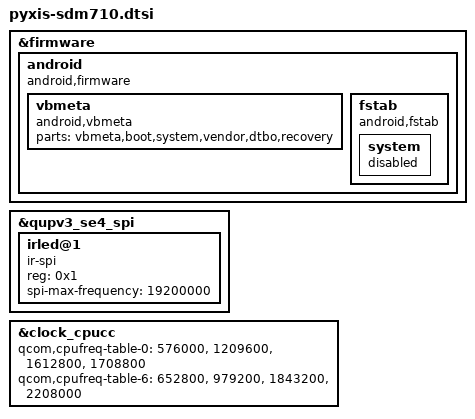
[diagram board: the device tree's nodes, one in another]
/* Copyright (c) 2018, The Linux Foundation. All rights reserved.
 * Copyright (C) 2020 XiaoMi, Inc.
 *
 * This program is free software; you can redistribute it and/or modify
 * it under the terms of the GNU General Public License version 2 and
 * only version 2 as published by the Free Software Foundation.
 *
 * This program is distributed in the hope that it will be useful,
 * but WITHOUT ANY WARRANTY; without even the implied warranty of
 * MERCHANTABILITY or FITNESS FOR A PARTICULAR PURPOSE.  See the
 * GNU General Public License for more details.
 */
#include "pyxis-cosmos-sdm710-common.dtsi"

&firmware {
	android {
		compatible = "android,firmware";
		vbmeta {
			compatible = "android,vbmeta";
			parts = "vbmeta,boot,system,vendor,dtbo,recovery";
		};

		fstab {
			compatible = "android,fstab";
			system {
				status = "disabled";
			};
		};
	};
};

&qupv3_se4_spi {
	status = "ok";
	irled@1 {
		compatible = "ir-spi";
		reg = <0x1>;
		status = "ok";
		spi-max-frequency = <19200000>;
	};
};

/* sdm670.dtsi */
&clock_cpucc {
	qcom,cpufreq-table-0 =
		<576000>,
		<1209600>,
		<1612800>,
		<1708800>;

	qcom,cpufreq-table-6 =
		<652800>,
		<979200>,
		<1843200>,
		<2208000>;
};
